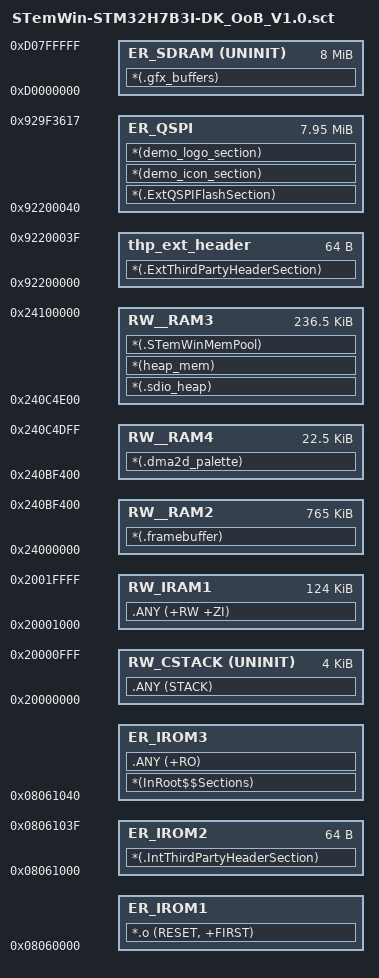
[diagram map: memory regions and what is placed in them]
; *************************************************************
; *** Scatter-Loading Description File generated by uVision ***
; *************************************************************
LR_IROM1 0x08060000   {    ; load region size_region
	ER_IROM1 0x08060000   {  ; load address = execution address
		*.o (RESET, +FIRST)
	}
	RW_CSTACK 0x20000000 UNINIT 0x00001000  {  ; RW data
		.ANY (STACK)
	}
	RW_IRAM1 0x20001000 0x0001F000  {  ; RW data
		.ANY (+RW +ZI)
	}
}

LR_IROM2 0x08061000     {    ; load region size_region
	ER_IROM2 0x08061000  0x40 { 
		*(.IntThirdPartyHeaderSection)
		}
	ER_IROM3 0x08061040  {
		*(InRoot$$Sections)
		.ANY (+RO) 
	}
	RW__RAM2  0x24000000 0xBF401{
	*(.framebuffer)
	}
	RW__RAM4  0x240bf400 0x5a00{
	*(.dma2d_palette)
	}
	RW__RAM3  0x240c4e00 0x3B201{
	*(.sdio_heap)
	*(heap_mem)
	*(.STemWinMemPool)
	}
	ER_SDRAM 0xD0000000 UNINIT 0x800000{ 
			*(.gfx_buffers)
		} 
}
LR_QSPI 0x92200000 0x800000 {
	thp_ext_header  0x92200000  0x40 { 
		*(.ExtThirdPartyHeaderSection) 
		}		
	ER_QSPI  0x92200040 0x7F35D8{
		*(.ExtQSPIFlashSection)
		*(demo_icon_section)
		*(demo_logo_section)
	}
}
